# USB_WRAPPER1 register map
Vendor: Texas Instruments
Peripheral module from a debugger description file (folder TDA2Px).
Registers are 32-bit, access not given, reset values left out (the file's numbers can be read two ways) unless marked. A register's access mark holds for its fields unless they carry their own. Offsets are as the file gives them; lines under a group give offsets from that group; [hi:lo] are bit positions; {n}, {i} and the like mark numbered series; 'fields as' and 'values as' point back to an identical list; <NAME> marks a mode.

## USB_WRAPPER1
0x00 USB_REVISION ro — USB_WRAPPER Revision Identifier
  [31:0] REVISION — USB_WRAPPER Revision
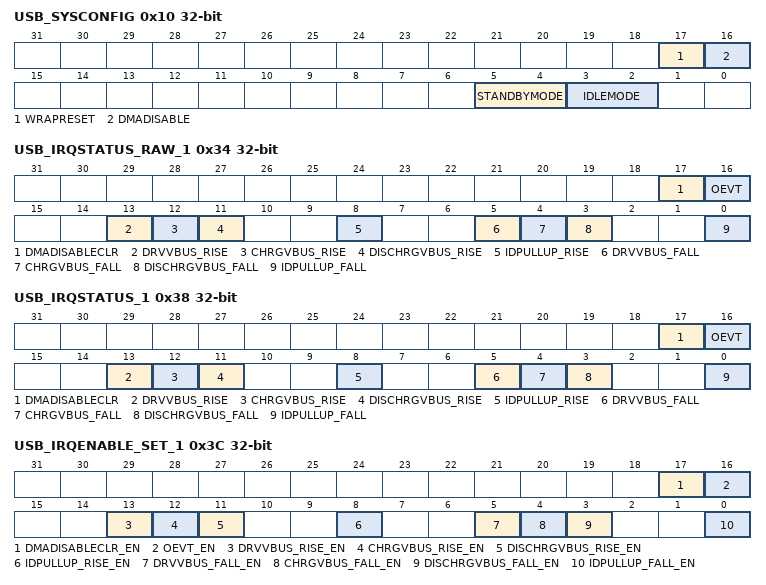
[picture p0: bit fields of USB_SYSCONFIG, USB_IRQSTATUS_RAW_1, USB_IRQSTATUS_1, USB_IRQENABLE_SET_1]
0x10 USB_SYSCONFIG access per field — Controls various parameters of the master and slave interfaces.
  [17] WRAPRESET rw — Software reset for the USB_WRAPPER register set. Self-clearing. Does not affect the core register set.
    0=noop (No action); 1=dorst (Request wrapper reset); 1=active (Wrapper reset is ongoing); 0=done (Wrapper reset is done / inactive)
  [16] DMADISABLE rw — Disable/Enable control of the DMA master (initiator) to block read/write accesses. Bit is auto-cleared (to 0) by HW in case of outgoing access, but must be set (to 1) manually.
    0=Enable the DMA. The enabling can also be done by the hardware, i.e. bit it auto-cleared.; 1=Disable the DMA. software must ensure that there are no ongoing transactions before setting this bit. The disabling can only be done by software.; 1=Disabled (DMA is disabled, outgoing read/write accesses are blocked. When in smart-standby mode, standby is requested.); 0=Enabled (DMA is enabled, outgoing read/write accesses are possible. When in smart-standby mode, standby exit is requested.)
  [5:4] STANDBYMODE rw — PM mode of local initiator (master). Initiator may generate read/write transaction as long as it is out of STANDBY state.
    0=Force-standby: initiator is unconditionally placed in standby state; 1=no (No-standby: initiator is unconditionally placed out of standby state.); 3=smart_wakeup (Smart-Standby, wakeup-capable: initiator's standby state depends on internal conditions, i.e. the module's functional requirements. Asynchronous wakeup events can be generated.); 2=Smart-standby: initiator's standby state depends on internal conditions, i.e. the module's functional requirements. Asynchronous wakeup events cannot be generated.
  [3:2] IDLEMODE rw — PM mode of local target (slave). Target shall be capable of handling read/write transaction as long as it is out of IDLE state.
    0=Force-idle mode: local target's idle state follows (acknowledges) the system's idle requests unconditionally, regardless of the IP module's internal requirements; 1=no (No-idle mode: local target never enters idle state.); 3=smart_wakeup (Smart-idle wakeup-capable mode: local target's idle state eventually follows (acknowledges) the system's idle requests, depending on the IP module's internal requirements. IP module may generate (IRQ- or DMA-request-related) wakeup events when in idle state.); 2=Smart-idle mode: local target's idle state eventually follows (acknowledges) the system's idle requests, depending on the IP module's internal requirements. Module shall not generate (IRQ- or DMA-request-related) wakeup events.
0x20 USB_IRQ_EOI access per field — Software End-Of-Interrupt: Allows the generation of further pulses on the interrupt line, if an new interrupt event is pending, when using the pulsed output. Unused when using the level interrupt line (depending on module integration).
  [4:0] LINE_NUMBER rw — Write the IRQ line number to apply SW EOI to it.
0x24 USB_IRQSTATUS_RAW_0 — Raw status of main core interrupt request. Set even if event is not enabled. Write 1 to set, used mostly for debug (regular status also gets set if enabled).
  [0] COREIRQ_ST — IRQ status for core: see status registerUSB_IMAN[0] IP (access RW W1toSet)
    0=No_action; 1=Trigger_IRQ_event_by_software; 1=IRQ_event_pending; 0=No_event_pending
0x28 USB_IRQSTATUS_0 — 'regular' status of main core interrupt request. Set only when enabled, self-cleared unless it was set by writing to, for debug. Write 1 to clear (raw status also gets cleared).
  [0] COREIRQ_ST — IRQ status for core: see status registerUSB_IMAN[0] IP (access RW W1toClr)
    0=noaction; 1=Clear pending event, if any; 1=pending (IRQ event pending); 0=none (No event pending)
0x2C USB_IRQENABLE_SET_0 — Enable of main core interrupt request. Write 1 to set (i.e. to enable interrupt). Readout is the same as corresponding _CLR register.
  [0] COREIRQ_EN — IRQ enable for main core interrupt (access RW W1toSet)
    0=noaction; 1=set (Set IRQ enable (i.e. enable event)); 1=enabled (IRQ event is enabled); 0=disabled (IRQ event is disabled)
0x30 USB_IRQENABLE_CLR_0 — Enable of main core interrupt request. Write 1 to clear (i.e. to disable interrupt). Readout is the same as corresponding _SET register.
  [0] COREIRQ_EN — IRQ enable for main core interrupt (access RW W1toClr)
    0=noaction; 1=Clear IRQ enable (i.e. disable event); 1=enabled (IRQ event is enabled); 0=disabled (IRQ event is disabled)
0x34 USB_IRQSTATUS_RAW_1 — Raw status of secondary interrupt requests. Set even if event is not enabled. Write 1 to set the (raw) status, mostly for debug (regular status also gets set).
  [all] fields
    0=noaction; 1=set (Trigger IRQ event by software); 1=pending (IRQ event pending); 0=none (No event pending)
  [17] DMADISABLECLR — DMA-disable self-clear IRQ status:USB_SYSCONFIG[17] DMADISABLE hardware-cleared (to 0) because of DMA access. Not triggered by a software clear. (access RW W1toSet)
  [16] OEVT — OTG event in core, IRQ status: see status registerUSB_OEVT (access RW W1toSet)
  [13] DRVVBUS_RISE — Drive VBUS control rise IRQ status (access RW W1toSet)
  [12] CHRGVBUS_RISE — Charge VBUS control rise IRQ status (access RW W1toSet)
  [11] DISCHRGVBUS_RISE — Discharge VBUS control rise IRQ status (access RW W1toSet)
  [8] IDPULLUP_RISE — ID pullup control rise IRQ status (access RW W1toSet)
  [5] DRVVBUS_FALL — Drive VBUS control fall IRQ status (access RW W1toSet)
  [4] CHRGVBUS_FALL — Charge VBUS control fall IRQ status (access RW W1toSet)
  [3] DISCHRGVBUS_FALL — Discharge VBUS control fall IRQ status (access RW W1toSet)
  [0] IDPULLUP_FALL — ID pullup control fall IRQ status (access RW W1toSet)
0x38 USB_IRQSTATUS_1 — Regular status of secondary interrupt requests. Set only when enabled. Write 1 to clear after interrupt is serviced (raw status also gets cleared).
  [all] fields
    values as USB_IRQSTATUS_0.COREIRQ_ST
  [17] DMADISABLECLR — DMA-disable self-clear IRQ status:USB_SYSCONFIG[17] DMADISABLE hardware-cleared (to 0) because of DMA access. Not triggered by a software clear. (access RW W1toClr)
  [16] OEVT — OTG event in core, IRQ status: see status registerUSB_OEVT. (access RW W1toClr)
  [13] DRVVBUS_RISE — Drive VBUS control rise IRQ status (access RW W1toClr)
  [12] CHRGVBUS_RISE — Charge VBUS control rise IRQ status (access RW W1toClr)
  [11] DISCHRGVBUS_RISE — Discharge VBUS control rise IRQ status (access RW W1toClr)
  [8] IDPULLUP_RISE — ID pullup control rise IRQ status (access RW W1toClr)
  [5] DRVVBUS_FALL — Drive VBUS control fall IRQ status (access RW W1toClr)
  [4] CHRGVBUS_FALL — Charge VBUS control fall IRQ status (access RW W1toClr)
  [3] DISCHRGVBUS_FALL — Discharge VBUS control fall IRQ status (access RW W1toClr)
  [0] IDPULLUP_FALL — ID pullup control fall IRQ status (access RW W1toClr)
0x3C USB_IRQENABLE_SET_1 — Enable secondary interrupt requests. Write 1 to set (that is, to enable interrupt). Readout is the same as corresponding _CLR register.
  [all] fields
    values as USB_IRQENABLE_SET_0.COREIRQ_EN
  [17] DMADISABLECLR_EN — DMA-disable self-clear, IRQ enable (access RW W1toSet)
  [16] OEVT_EN — OTG event in core, IRQ enable (access RW W1toSet)
  [13] DRVVBUS_RISE_EN — Drive VBUS control rise IRQ enable (access RW W1toSet)
  [12] CHRGVBUS_RISE_EN — Charge VBUS control rise IRQ enable (access RW W1toSet)
  [11] DISCHRGVBUS_RISE_EN — Discharge VBUS control rise IRQ enable (access RW W1toSet)
  [8] IDPULLUP_RISE_EN — ID pullup control rise IRQ enable (access RW W1toSet)
  [5] DRVVBUS_FALL_EN — Drive VBUS control fall IRQ enable (access RW W1toSet)
  [4] CHRGVBUS_FALL_EN — Charge VBUS control fall IRQ enable (access RW W1toSet)
  [3] DISCHRGVBUS_FALL_EN — Discharge VBUS control fall IRQ enable (access RW W1toSet)
  [0] IDPULLUP_FALL_EN — ID pullup control fall IRQ enable (access RW W1toSet)
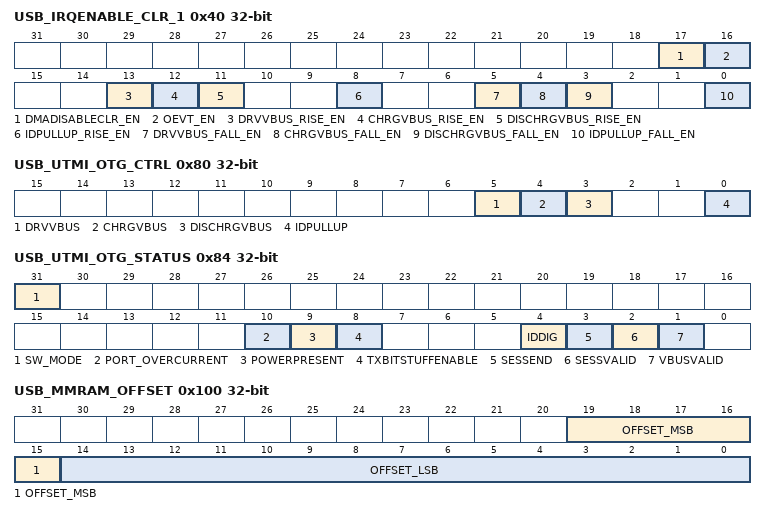
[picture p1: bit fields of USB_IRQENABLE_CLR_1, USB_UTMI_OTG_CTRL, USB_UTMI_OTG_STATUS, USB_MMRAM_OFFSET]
0x40 USB_IRQENABLE_CLR_1 — Enable secondary interrupt requests. Write 1 to clear (that is, to disable interrupt). Readout is the same as corresponding _SET register.
  [all] fields
    values as USB_IRQENABLE_CLR_0.COREIRQ_EN
  [17] DMADISABLECLR_EN — DMA-disable self-clear, IRQ enable (access RW W1toClr)
  [16] OEVT_EN — OTG event in core, IRQ enable (access RW W1toClr)
  [13] DRVVBUS_RISE_EN — Drive VBUS control rise IRQ enable (access RW W1toClr)
  [12] CHRGVBUS_RISE_EN — Charge VBUS control rise IRQ enable (access RW W1toClr)
  [11] DISCHRGVBUS_RISE_EN — Discharge VBUS control rise IRQ enable (access RW W1toClr)
  [8] IDPULLUP_RISE_EN — ID pullup control rise IRQ enable (access RW W1toClr)
  [5] DRVVBUS_FALL_EN — Drive VBUS control fall IRQ enable (access RW W1toClr)
  [4] CHRGVBUS_FALL_EN — Charge VBUS control fall IRQ enable (access RW W1toClr)
  [3] DISCHRGVBUS_FALL_EN — Discharge VBUS control fall IRQ enable (access RW W1toClr)
  [0] IDPULLUP_FALL_EN — ID pullup control fall IRQ enable (access RW W1toClr)
0x80 USB_UTMI_OTG_CTRL ro
  [5] DRVVBUS — Drive 5V on VBUS. Plays the role of 'hub_vbus_ctrl' in non-OTG host mode.
    1=drive VBUS; 0=noaction
  [4] CHRGVBUS — Charge VBUS through a resistor for VBUS-pulsing SRP.
    1=charge VBUS; 0=noaction
  [3] DISCHRGVBUS — Discharge VBUS through a resistor, until the session-end VBUS state is reached.
    1=discharge VBUS; 0=NoAction
  [0] IDPULLUP — Pull-up to the (OTG) ID line to allow its sampling
    1=Enable sampling of ID line; 0=Disable sampling of ID line
0x84 USB_UTMI_OTG_STATUS access per field
  [31] SW_MODE rw — Controls the source of UTMI / PIPE status for VBUS and OTG ID (vbusvalid, sessvalid, sessend, iddig, powerpresent)
    0=io (Hardware mode: OTG ID and VBUS status for the USB controller are taken from the UTMI inputs signals); 1=sw (Software mode: OTG ID and VBUS status for the USB controller are taken from the fields of the current register.)
  [10] PORT_OVERCURRENT rw — Over-current status, for non-OTG host only.
    0=none (No over-current indication); 1=oc (Over-current indication)
  [9] POWERPRESENT rw — Software-programmed value of PIPE3.0 PowerPresent (VBUS status) seen by the core, alternative to HW input.
  [8] TXBITSTUFFENABLE rw — Software-programmed UTMI output txbitstuffenable[h] Note: as per UTMI+, used only in UTMI Opmode 0b11 (i.e. SYNC and EOP generation disabled)
    0=nobs (No bitstuffing); 1=bs (Data bitstuffing enabled)
  [4] IDDIG rw — Software-programmed value of UTMI+ IdDig (OTG ID status) seen by the core, alternative to hardware input. Don't care until IdPullup = 1 for at least 50 ms
    0=IdA (ID pin is grounded = OTG A = default Host); 1=IdB (ID pin is floating = OTG B = default Peripheral)
  [3] SESSEND rw — Software-programmed value of UTMI+ SessEnd (VBUS status) seen by the core, alternative to HW input.
    0=notended (VBUS is above Session-End threshold); 1=ended (VBUS is below Session-End threshold)
  [2] SESSVALID rw — Software-programmed value of UTMI+ SessValid (VBUS status) seen by the core, alternative to hardware inputs AValid and BValid.
    0=notvalid (VBUS is below Session-Valid threshold); 1=valid (VBUS is above Session-Valid threshold)
  [1] VBUSVALID rw — Software-programmed value of UTMI+ VbusValid (VBUS status) seen by the core, alternative to hardware input.
    0=notvalid (VBUS is below Vbus-Valid threshold.); 1=valid (VBUS is above Vbus-Valid threshold)
0x100 USB_MMRAM_OFFSET access per field — Offset of Memory-mapped RAM accesses. Page is remapped from 0x8000 to 0xFFFF (32 KiB)
  [19:15] OFFSET_MSB rw — Byte offset MSBits = page offset
    0=core_bot (Page offset for core register set, lower half. DO NOT USE: use static access at offset 0x1_0000+ instead.); 1=core_top (Page offset for core register set, upper half. DO NOT USE: use static access at offset 0x1_0000+ instead.); 24=RAM2_base (Base page offset for RAM2 (= core byte address 0xC_0000) The RAM shall fit inside this page for up to 32 kByte = 8,192 x 64-bit words.); 16=RAM1_base (Base page offset for RAM1 (= core byte address 0x8_0000): Tx FIFOs. The RAM shall fit inside this page for up to 32 kByte = 8,192 x 64-bit words.); 8=RAM0_base (Base page offset for RAM0 (= core byte address 0x4_0000): Rx FIFOs, descriptors, registers. The RAM shall fit inside this page for up to 32 kByte = 8,192 x 64-bit words)
  [14:0] OFFSET_LSB ro — Byte offset LSBits, always 0
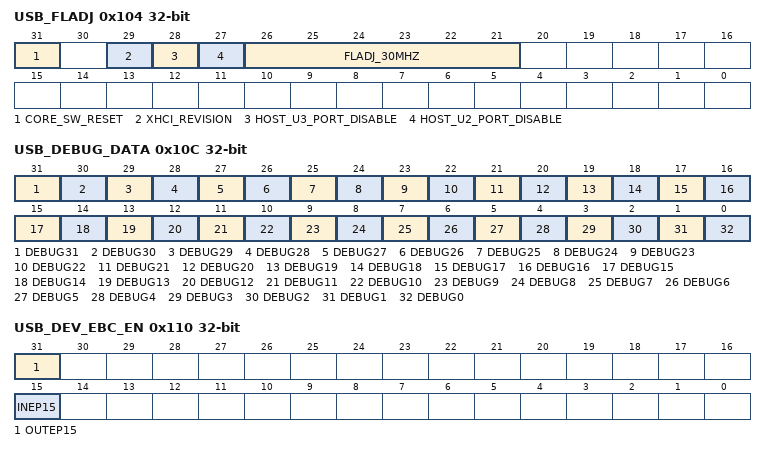
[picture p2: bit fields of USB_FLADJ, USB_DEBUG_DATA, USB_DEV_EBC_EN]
0x104 USB_FLADJ access per field — Jitter adjustment and other pseudo-static parameters
  [31] CORE_SW_RESET rw — Active-high core software reset. Static, i.e. not self-clearing. After clearing, wait for reset completion by polling USB_USBSTS[11] CNR bit.
    0=noreset (Reset inactive); 1=Reset active
  [29] XHCI_REVISION rw — Switches to the legacy xHCI 0.96 host SW API mode. Changes shall take place under core software reset: [31] CORE_SW_RESET = 1.
    0=xHCI version 0.96; 1=xHCI version 1.0 + errata
  [28] HOST_U3_PORT_DISABLE rw — USB3.0 port disable, overriding xHCI driver.
    0=en (Port can be enabled.); 1=dis (Port stops reporting connect/disconnect events and remains in disabled state.)
  [27] HOST_U2_PORT_DISABLE rw — USB2.0 port disable, overriding xHCI driver.
    values as HOST_U3_PORT_DISABLE
  [26:21] FLADJ_30MHZ rw — HS Jitter Adjustment, in 30-MHz periods
0x108 USB_DEBUG_CFG access per field — Configuration of debug output (observability)
  [2:0] SEL rw — selection of observed local signals
    1=UTMI (Debug output is a selection of UTMI (USB2.0 PHY) interface signals); 0=tielo (Debug output is tied low (32'b0)); 2=PIPE (Debug output is a selection of PIPE (USB3.0 PHY) interface signals); 4=Trace_lo (Debug output is lower 32 bits controller core's internal trace vector, selected by[21:16] TRACEPORTMUXSEL); 5=Trace_hi (Debug output is upper 32 bits controller core's internal trace vector, selected by[21:16] TRACEPORTMUXSEL); 3=Core (Debug output is controller core's internal debug signals)
0x10C USB_DEBUG_DATA ro — Data currently visible on DEBUG output (observability) port See [2:0] SEL bit field.
  [31] DEBUG31 — SEL = 1: utmi_sessend SEL = 2: pipe_rxstatus[2] SEL = 3: core_sm2bl_cur_mode
  [30] DEBUG30 — SEL = 1: utmi_vbusvalid SEL = 2: pipe_rxstatus[1] SEL = 3: core_suspend_n
  [29] DEBUG29 — SEL = 1: utmi_bvalid SEL = 2: pipe_rxstatus[0] SEL = 3: core_suspend_com_n
  [28] DEBUG28 — SEL = 1: utmi_avalid SEL = 2: pipe_elecidle SEL = 3: core_u2_dssr_state[3]
  [27] DEBUG27 — SEL = 1: utmi_iddig SEL = 2: pipe_phystatus SEL = 3: core_u2_dssr_state[2]
  [26] DEBUG26 — SEL = 1: utmi_hostdisconnect SEL = 2: pipe_rxvalid SEL = 3: core_u2_dssr_state[1]
  [25] DEBUG25 — SEL = 1: utmi_txbitstuffenableh SEL = 2: pipe_rxdatak[3] SEL = 3: core_u2_dssr_state[0]
  [24] DEBUG24 — SEL = 1: utmi_txbitstuffenable SEL = 2: pipe_rxdatak[2] SEL = 3: core_u2mac_txrx_state_1[4]
  [23] DEBUG23 — SEL = 1: utmi_dischrgvbus SEL = 2: pipe_rxdatak[1] SEL = 3: core_u2mac_txrx_state_1[3]
  [22] DEBUG22 — SEL = 1: utmi_chrgvbus SEL = 2: pipe_rxdatak[0] SEL = 3: core_u2mac_txrx_state_1[2]
  [21] DEBUG21 — SEL = 1: utmi_drvvbus SEL = 2: pipe_rxpclk SEL = 3: core_u2mac_txrx_state_1[1]
  [20] DEBUG20 — SEL = 1: utmi_dmpulldown SEL = 2: pipe_rxtermination SEL = 3: core_u2mac_txrx_state_1[0]
  [19] DEBUG19 — SEL = 1: utmi_dppulldown SEL = 2: pipe_txswing SEL = 3: core_u2mac_txrx_state_0[4]
  [18] DEBUG18 — SEL = 1: utmi_idpullup SEL = 2: pipe_txmargin[2] SEL = 3: core_u2mac_txrx_state_0[3]
  [17] DEBUG17 — SEL = 1: utmi_linestate[1] SEL = 2: pipe_txmargin[1] SEL = 3: core_u2mac_txrx_state_0[2]
  [16] DEBUG16 — SEL = 1: utmi_linestate[0] SEL = 2: pipe_txmargin[0] SEL = 3: core_u2mac_txrx_state_0[1]
  [15] DEBUG15 — SEL = 1: utmi_opmode[1] SEL = 2: pipe_txdeemph[1] SEL = 3: core_u2mac_txrx_state_0[0]
  [14] DEBUG14 — SEL = 1: utmi_opmode[0] SEL = 2: pipe_txdeemph[0] SEL = 3: core_u2_prt_state[4]
  [13] DEBUG13 — SEL = 1: utmi_termSELect SEL = 2: pipe_powerdown[1] SEL = 3: core_u2_prt_state[3]
  [12] DEBUG12 — SEL = 1: utmi_xcvrselect[1] SEL = 2: pipe_powerdown[0] SEL = 3: core_u2_prt_state[2]
  [11] DEBUG11 — SEL = 1: utmi_xcvrselect[0] SEL = 2: pipe_reset_n SEL = 3: core_u2_prt_state[1]
  [10] DEBUG10 — SEL = 1: utmi_suspendm SEL = 2: pipe_rxeqtraining SEL = 3: core_u2_prt_state[0]
  [9] DEBUG9 — SEL = 1: utmi_reset SEL = 2: pipe_rxpolarity SEL = 3: core_gsts_buserraddvld
  [8] DEBUG8 — SEL = 1: utmi_rxerror SEL = 2: pipe_txoneszeros SEL = 3: debug_mclk_usof_number[0]
  [7] DEBUG7 — SEL = 1: utmi_rxvalidh SEL = 2: pipe_txelecidle SEL = 3: core_ltdb_link_state[3]
  [6] DEBUG6 — SEL = 1: utmi_rxvalid SEL = 2: pipe_txdetectrxloopback SEL = 3: core_ltdb_link_state[2]
  [5] DEBUG5 — SEL = 1: utmi_rxactive SEL = 2: pipe_elasticitybuffermode SEL = 3: core_ltdb_link_state[1]
  [4] DEBUG4 — SEL = 1: utmi_txready SEL = 2: pipe_txdatak[3] SEL = 3: core_ltdb_link_state[0]
  [3] DEBUG3 — SEL = 1: utmi_txvalidh SEL = 2: pipe_txdatak[2] SEL = 3: core_ltdb_substate[3]
  [2] DEBUG2 — SEL = 1: utmi_txvalid SEL = 2: pipe_txdatak[1] SEL = 3: core_ltdb_substate[2]
  [1] DEBUG1 — SEL = 1: utmi_databus16_8 SEL = 2: pipe_txdatak[0] SEL = 3: core_ltdb_substate[1]
  [0] DEBUG0 — SEL = 1: utmi_clk SEL = 2: pipe_txpclk SEL = 3: core_ltdb_substate[0]
0x110 USB_DEV_EBC_EN access per field — Enable External Buffer Control (EBC) for selected endpoints. Device mode only.
  [31] OUTEP15 rw — Enable EBC HW throttling for OUT EP 15 (USB receive)
    0=dis (EBC disabled); 1=en (EBC enabled.[15] shall also be set to 1 in DEPCFG command for this EP.)
  [15] INEP15 rw — Enable EBC HW throttling for IN EP 15 (USB transmit)
    values as OUTEP15
